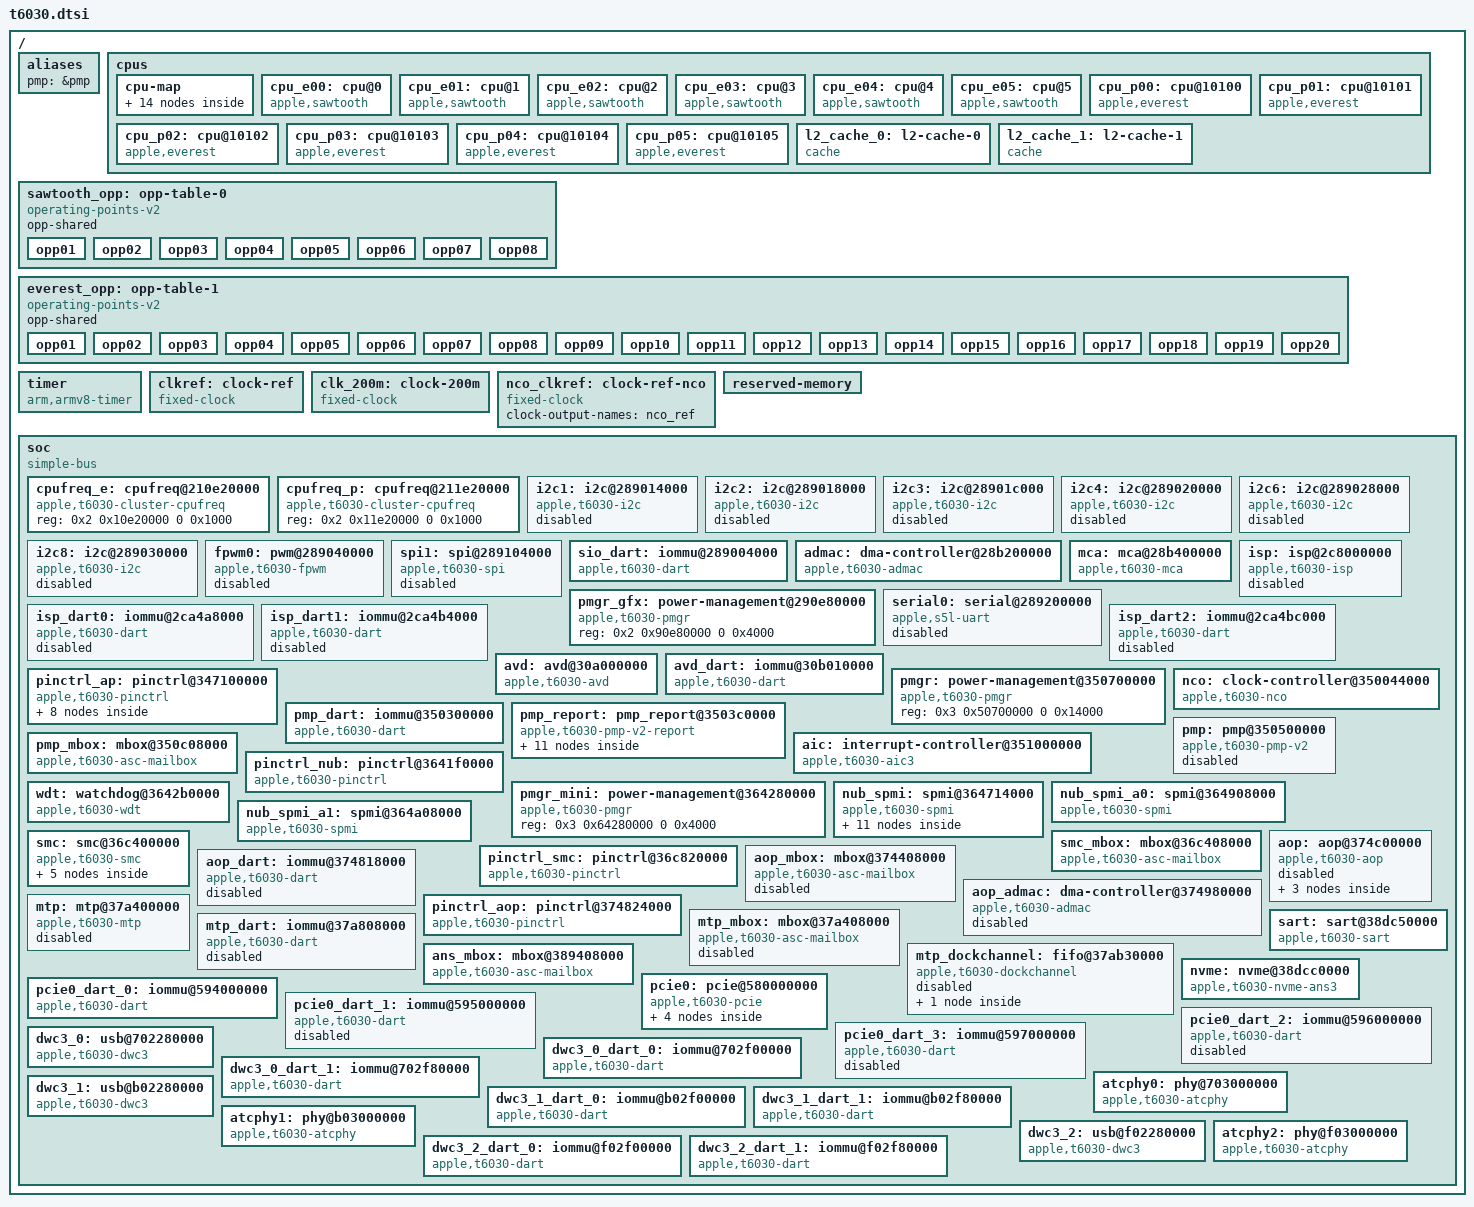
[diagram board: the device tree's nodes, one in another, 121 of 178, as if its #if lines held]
// SPDX-License-Identifier: GPL-2.0+ OR MIT
/*
 * Apple T6030 "M3 Pro" SoC
 *
 * Other names: H15J, "Lobos"
 *
 * Copyright The Asahi Linux Contributors
 */

#include <dt-bindings/gpio/gpio.h>
#include <dt-bindings/interrupt-controller/apple-aic.h>
#include <dt-bindings/interrupt-controller/irq.h>
#include <dt-bindings/pinctrl/apple.h>
#include <dt-bindings/phy/phy.h>
#include <dt-bindings/spmi/spmi.h>

/ {
	#address-cells = <2>;
	#size-cells = <2>;

	aliases {
		#ifdef APPLE_USE_PMP
		pmp = &pmp;
		#endif
	};

	cpus {
		#address-cells = <2>;
		#size-cells = <0>;

		cpu-map {
			cluster0 {
				core0 {
					cpu = <&cpu_e00>;
				};
				core1 {
					cpu = <&cpu_e01>;
				};
				core2 {
					cpu = <&cpu_e02>;
				};
				core3 {
					cpu = <&cpu_e03>;
				};
				core4 {
					cpu = <&cpu_e04>;
				};
				core5 {
					cpu = <&cpu_e05>;
				};
			};

			cluster1 {
				core0 {
					cpu = <&cpu_p00>;
				};
				core1 {
					cpu = <&cpu_p01>;
				};
				core2 {
					cpu = <&cpu_p02>;
				};
				core3 {
					cpu = <&cpu_p03>;
				};
				core4 {
					cpu = <&cpu_p04>;
				};
				core5 {
					cpu = <&cpu_p05>;
				};
			};
		};

		cpu_e00: cpu@0 {
			compatible = "apple,sawtooth";
			device_type = "cpu";
			reg = <0x0 0x0>;
			enable-method = "spin-table";
			cpu-release-addr = <0 0>; /* to be filled by loader */
			next-level-cache = <&l2_cache_0>;
			i-cache-size = <0x20000>;
			d-cache-size = <0x10000>;
			operating-points-v2 = <&sawtooth_opp>;
			capacity-dmips-mhz = <851>;
			performance-domains = <&cpufreq_e>;
		};

		cpu_e01: cpu@1 {
			compatible = "apple,sawtooth";
			device_type = "cpu";
			reg = <0x0 0x1>;
			enable-method = "spin-table";
			cpu-release-addr = <0 0>; /* to be filled by loader */
			next-level-cache = <&l2_cache_0>;
			i-cache-size = <0x20000>;
			d-cache-size = <0x10000>;
			operating-points-v2 = <&sawtooth_opp>;
			capacity-dmips-mhz = <851>;
			performance-domains = <&cpufreq_e>;
		};

		cpu_e02: cpu@2 {
			compatible = "apple,sawtooth";
			device_type = "cpu";
			reg = <0x0 0x2>;
			enable-method = "spin-table";
			cpu-release-addr = <0 0>; /* to be filled by loader */
			next-level-cache = <&l2_cache_0>;
			i-cache-size = <0x20000>;
			d-cache-size = <0x10000>;
			operating-points-v2 = <&sawtooth_opp>;
			capacity-dmips-mhz = <851>;
			performance-domains = <&cpufreq_e>;
		};

		cpu_e03: cpu@3 {
			compatible = "apple,sawtooth";
			device_type = "cpu";
			reg = <0x0 0x3>;
			enable-method = "spin-table";
			cpu-release-addr = <0 0>; /* to be filled by loader */
			next-level-cache = <&l2_cache_0>;
			i-cache-size = <0x20000>;
			d-cache-size = <0x10000>;
			operating-points-v2 = <&sawtooth_opp>;
			capacity-dmips-mhz = <851>;
			performance-domains = <&cpufreq_e>;
		};

		cpu_e04: cpu@4 {
			compatible = "apple,sawtooth";
			device_type = "cpu";
			reg = <0x0 0x4>;
			enable-method = "spin-table";
			cpu-release-addr = <0 0>; /* to be filled by loader */
			next-level-cache = <&l2_cache_0>;
			i-cache-size = <0x20000>;
			d-cache-size = <0x10000>;
			operating-points-v2 = <&sawtooth_opp>;
			capacity-dmips-mhz = <851>;
			performance-domains = <&cpufreq_e>;
		};

		cpu_e05: cpu@5 {
			compatible = "apple,sawtooth";
			device_type = "cpu";
			reg = <0x0 0x5>;
			enable-method = "spin-table";
			cpu-release-addr = <0 0>; /* to be filled by loader */
			next-level-cache = <&l2_cache_0>;
			i-cache-size = <0x20000>;
			d-cache-size = <0x10000>;
			operating-points-v2 = <&sawtooth_opp>;
			capacity-dmips-mhz = <851>;
			performance-domains = <&cpufreq_e>;
		};

		cpu_p00: cpu@10100 {
			compatible = "apple,everest";
			device_type = "cpu";
			reg = <0x0 0x10100>;
			enable-method = "spin-table";
			cpu-release-addr = <0 0>; /* To be filled by loader */
			next-level-cache = <&l2_cache_1>;
			i-cache-size = <0x30000>;
			d-cache-size = <0x20000>;
			operating-points-v2 = <&everest_opp>;
			capacity-dmips-mhz = <1024>;
			performance-domains = <&cpufreq_p>;
		};

		cpu_p01: cpu@10101 {
			compatible = "apple,everest";
			device_type = "cpu";
			reg = <0x0 0x10101>;
			enable-method = "spin-table";
			cpu-release-addr = <0 0>; /* To be filled by loader */
			next-level-cache = <&l2_cache_1>;
			i-cache-size = <0x30000>;
			d-cache-size = <0x20000>;
			operating-points-v2 = <&everest_opp>;
			capacity-dmips-mhz = <1024>;
			performance-domains = <&cpufreq_p>;
		};

		cpu_p02: cpu@10102 {
			compatible = "apple,everest";
			device_type = "cpu";
			reg = <0x0 0x10102>;
			enable-method = "spin-table";
			cpu-release-addr = <0 0>; /* To be filled by loader */
			next-level-cache = <&l2_cache_1>;
			i-cache-size = <0x30000>;
			d-cache-size = <0x20000>;
			operating-points-v2 = <&everest_opp>;
			capacity-dmips-mhz = <1024>;
			performance-domains = <&cpufreq_p>;
		};

		cpu_p03: cpu@10103 {
			compatible = "apple,everest";
			device_type = "cpu";
			reg = <0x0 0x10103>;
			enable-method = "spin-table";
			cpu-release-addr = <0 0>; /* To be filled by loader */
			next-level-cache = <&l2_cache_1>;
			i-cache-size = <0x30000>;
			d-cache-size = <0x20000>;
			operating-points-v2 = <&everest_opp>;
			capacity-dmips-mhz = <1024>;
			performance-domains = <&cpufreq_p>;
		};

		cpu_p04: cpu@10104 {
			compatible = "apple,everest";
			device_type = "cpu";
			reg = <0x0 0x10104>;
			enable-method = "spin-table";
			cpu-release-addr = <0 0>; /* To be filled by loader */
			next-level-cache = <&l2_cache_1>;
			i-cache-size = <0x30000>;
			d-cache-size = <0x20000>;
			operating-points-v2 = <&everest_opp>;
			capacity-dmips-mhz = <1024>;
			performance-domains = <&cpufreq_p>;
		};

		cpu_p05: cpu@10105 {
			compatible = "apple,everest";
			device_type = "cpu";
			reg = <0x0 0x10105>;
			enable-method = "spin-table";
			cpu-release-addr = <0 0>; /* To be filled by loader */
			next-level-cache = <&l2_cache_1>;
			i-cache-size = <0x30000>;
			d-cache-size = <0x20000>;
			operating-points-v2 = <&everest_opp>;
			capacity-dmips-mhz = <1024>;
			performance-domains = <&cpufreq_p>;
		};

		l2_cache_0: l2-cache-0 {
			compatible = "cache";
			cache-level = <2>;
			cache-unified;
			cache-size = <0x400000>;
		};

		l2_cache_1: l2-cache-1 {
			compatible = "cache";
			cache-level = <2>;
			cache-unified;
			cache-size = <0x1000000>;
		};
	};

	sawtooth_opp: opp-table-0 {
		compatible = "operating-points-v2";
		opp-shared;

		opp01 {
			opp-hz = /bits/ 64 <744000000>;
			opp-level = <1>;
			clock-latency-ns = <7700>;
		};
		opp02 {
			opp-hz = /bits/ 64 <1044000000>;
			opp-level = <2>;
			clock-latency-ns = <21200>;
		};
		opp03 {
			opp-hz = /bits/ 64 <1476000000>;
			opp-level = <3>;
			clock-latency-ns = <26400>;
		};
		opp04 {
			opp-hz = /bits/ 64 <2004000000>;
			opp-level = <4>;
			clock-latency-ns = <40500>;
		};
		opp05 {
			opp-hz = /bits/ 64 <2268000000>;
			opp-level = <5>;
			clock-latency-ns = <44400>;
		};
		opp06 {
			opp-hz = /bits/ 64 <2448000000>;
			opp-level = <6>;
			clock-latency-ns = <47200>;
		};
		opp07 {
			opp-hz = /bits/ 64 <2640000000>;
			opp-level = <7>;
			clock-latency-ns = <52000>;
		};
		opp08 {
			opp-hz = /bits/ 64 <2748000000>;
			opp-level = <8>;
			clock-latency-ns = <52000>;
		};
	};

	everest_opp: opp-table-1 {
		compatible = "operating-points-v2";
		opp-shared;

		opp01 {
			opp-hz = /bits/ 64 <696000000>;
			opp-level = <1>;
			clock-latency-ns = <8600>;
		};
		opp02 {
			opp-hz = /bits/ 64 <1092000000>;
			opp-level = <2>;
			clock-latency-ns = <18700>;
		};
		opp03 {
			opp-hz = /bits/ 64 <1356000000>;
			opp-level = <3>;
			clock-latency-ns = <20700>;
		};
		opp04 {
			opp-hz = /bits/ 64 <1596000000>;
			opp-level = <4>;
			clock-latency-ns = <24800>;
		};
		opp05 {
			opp-hz = /bits/ 64 <1884000000>;
			opp-level = <5>;
			clock-latency-ns = <30700>;
		};
		opp06 {
			opp-hz = /bits/ 64 <2172000000>;
			opp-level = <6>;
			clock-latency-ns = <34400>;
		};
		opp07 {
			opp-hz = /bits/ 64 <2424000000>;
			opp-level = <7>;
			clock-latency-ns = <39600>;
		};
		opp08 {
			opp-hz = /bits/ 64 <2616000000>;
			opp-level = <8>;
			clock-latency-ns = <40000>;
		};
		opp09 {
			opp-hz = /bits/ 64 <2808000000>;
			opp-level = <9>;
			clock-latency-ns = <41800>;
		};
		opp10 {
			opp-hz = /bits/ 64 <2988000000>;
			opp-level = <10>;
			clock-latency-ns = <45300>;
		};
		opp11 {
			opp-hz = /bits/ 64 <3144000000>;
			opp-level = <11>;
			clock-latency-ns = <46700>;
		};
		opp12 {
			opp-hz = /bits/ 64 <3288000000>;
			opp-level = <12>;
			clock-latency-ns = <49200>;
		};
		opp13 {
			opp-hz = /bits/ 64 <3420000000>;
			opp-level = <13>;
			clock-latency-ns = <53900>;
		};
		opp14 {
			opp-hz = /bits/ 64 <3576000000>;
			opp-level = <14>;
			clock-latency-ns = <53700>;
		};
		opp15 {
			opp-hz = /bits/ 64 <3624000000>;
			opp-level = <15>;
			clock-latency-ns = <54000>;
		};
		opp16 {
			opp-hz = /bits/ 64 <3708000000>;
			opp-level = <16>;
			clock-latency-ns = <54000>;
		};
		opp17 {
			opp-hz = /bits/ 64 <3780000000>;
			opp-level = <17>;
			clock-latency-ns = <54100>;
		};
		opp18 {
			opp-hz = /bits/ 64 <3864000000>;
			opp-level = <18>;
			clock-latency-ns = <54300>;
		};
		opp19 {
			opp-hz = /bits/ 64 <3960000000>;
			opp-level = <19>;
			clock-latency-ns = <58400>;
		};
		opp20 {
			opp-hz = /bits/ 64 <4056000000>;
			opp-level = <20>;
			clock-latency-ns = <58700>;
		};
	};

	timer {
		compatible = "arm,armv8-timer";
		interrupt-parent = <&aic>;
		interrupt-names = "phys", "virt", "hyp-phys", "hyp-virt";
		interrupts = <AIC_FIQ AIC_TMR_GUEST_PHYS IRQ_TYPE_LEVEL_HIGH>,
			     <AIC_FIQ AIC_TMR_GUEST_VIRT IRQ_TYPE_LEVEL_HIGH>,
			     <AIC_FIQ AIC_TMR_HV_PHYS IRQ_TYPE_LEVEL_HIGH>,
			     <AIC_FIQ AIC_TMR_HV_VIRT IRQ_TYPE_LEVEL_HIGH>;
	};

	clkref: clock-ref {
		compatible = "fixed-clock";
		#clock-cells = <0>;
		clock-frequency = <24000000>;
		clock-output-names = "clkref";
	};

	clk_200m: clock-200m {
		compatible = "fixed-clock";
		#clock-cells = <0>;
		clock-frequency = <200000000>;
		clock-output-names = "clk_200m";
	};

	/*
	 * This is a fabulated representation of the input clock
	 * to NCO since we don't know the true clock tree.
	 */
	nco_clkref: clock-ref-nco {
		compatible = "fixed-clock";
		#clock-cells = <0>;
		clock-output-names = "nco_ref";
	};

	reserved-memory {
		#address-cells = <2>;
		#size-cells = <2>;
		ranges;
	};

	soc: soc {
		compatible = "simple-bus";
		#address-cells = <2>;
		#size-cells = <2>;

		ranges;
		nonposted-mmio;
		/* Required to get >32-bit DMA via DARTs */
		dma-ranges = <0 0 0 0 0xffffffff 0xffffc000>;

		cpufreq_e: cpufreq@210e20000 {
			compatible = "apple,t6030-cluster-cpufreq", "apple,t8112-cluster-cpufreq";
			reg = <0x2 0x10e20000 0 0x1000>;
			#performance-domain-cells = <0>;
		};

		cpufreq_p: cpufreq@211e20000 {
			compatible = "apple,t6030-cluster-cpufreq", "apple,t8112-cluster-cpufreq";
			reg = <0x2 0x11e20000 0 0x1000>;
			#performance-domain-cells = <0>;
		};

		i2c1: i2c@289014000 {
			compatible = "apple,t6030-i2c", "apple,t8103-i2c";
			reg = <0x2 0x89014000 0x0 0x4000>;
			clocks = <&clkref>;
			interrupt-parent = <&aic>;
			interrupts = <AIC_IRQ 890 IRQ_TYPE_LEVEL_HIGH>;
			pinctrl-0 = <&i2c1_pins>;
			pinctrl-names = "default";
			#address-cells = <0x1>;
			#size-cells = <0x0>;
			power-domains = <&ps_i2c1>;
			status = "disabled";
		};

		i2c2: i2c@289018000 {
			compatible = "apple,t6030-i2c", "apple,t8103-i2c";
			reg = <0x2 0x89018000 0x0 0x4000>;
			clocks = <&clkref>;
			interrupt-parent = <&aic>;
			interrupts = <AIC_IRQ 891 IRQ_TYPE_LEVEL_HIGH>;
			pinctrl-0 = <&i2c2_pins>;
			pinctrl-names = "default";
			#address-cells = <0x1>;
			#size-cells = <0x0>;
			power-domains = <&ps_i2c2>;
			status = "disabled";
		};

		i2c3: i2c@28901c000 {
			compatible = "apple,t6030-i2c", "apple,t8103-i2c";
			reg = <0x2 0x8901c000 0x0 0x4000>;
			clocks = <&clkref>;
			interrupt-parent = <&aic>;
			interrupts = <AIC_IRQ 892 IRQ_TYPE_LEVEL_HIGH>;
			pinctrl-0 = <&i2c3_pins>;
			pinctrl-names = "default";
			#address-cells = <0x1>;
			#size-cells = <0x0>;
			power-domains = <&ps_i2c3>;
			status = "disabled";
		};

		i2c4: i2c@289020000 {
			compatible = "apple,t6030-i2c", "apple,t8103-i2c";
			reg = <0x2 0x89020000 0x0 0x4000>;
			clocks = <&clkref>;
			interrupt-parent = <&aic>;
			interrupts = <AIC_IRQ 893 IRQ_TYPE_LEVEL_HIGH>;
			pinctrl-0 = <&i2c4_pins>;
			pinctrl-names = "default";
			#address-cells = <0x1>;
			#size-cells = <0x0>;
			power-domains = <&ps_i2c4>;
			status = "disabled";
		};

		i2c6: i2c@289028000 {
			compatible = "apple,t6030-i2c", "apple,t8103-i2c";
			reg = <0x2 0x89028000 0x0 0x4000>;
			clocks = <&clkref>;
			interrupt-parent = <&aic>;
			interrupts = <AIC_IRQ 895 IRQ_TYPE_LEVEL_HIGH>;
			pinctrl-0 = <&i2c6_pins>;
			pinctrl-names = "default";
			#address-cells = <0x1>;
			#size-cells = <0x0>;
			power-domains = <&ps_i2c6>;
			status = "disabled";
		};

		i2c8: i2c@289030000 {
			compatible = "apple,t6030-i2c", "apple,t8103-i2c";
			reg = <0x2 0x89030000 0x0 0x4000>;
			clocks = <&clkref>;
			interrupt-parent = <&aic>;
			interrupts = <AIC_IRQ 897 IRQ_TYPE_LEVEL_HIGH>;
			pinctrl-0 = <&i2c8_pins>;
			pinctrl-names = "default";
			#address-cells = <0x1>;
			#size-cells = <0x0>;
			power-domains = <&ps_i2c8>;
			status = "disabled";
		};

		fpwm0: pwm@289040000 {
			compatible = "apple,t6030-fpwm", "apple,s5l-fpwm";
			reg = <0x2 0x89040000 0x0 0x4000>;
			power-domains = <&ps_fpwm0>;
			clocks = <&clkref>;
			#pwm-cells = <2>;
			status = "disabled";
		};

		spi1: spi@289104000 {
			compatible = "apple,t6030-spi", "apple,t8103-spi";
			reg = <0x2 0x89104000 0x0 0x4000>;
			interrupt-parent = <&aic>;
			interrupts = <AIC_IRQ 875 IRQ_TYPE_LEVEL_HIGH>;
			#address-cells = <1>;
			#size-cells = <0>;
			clocks = <&clk_200m>;
			pinctrl-0 = <&spi1_pins>;
			pinctrl-names = "default";
			power-domains = <&ps_spi1>;
			status = "disabled";
		};

		sio_dart: iommu@289004000 {
			compatible = "apple,t6030-dart", "apple,t8110-dart";
			reg = <0x2 0x89004000 0x0 0x4000>;
			interrupt-parent = <&aic>;
			interrupts = <AIC_IRQ 901 IRQ_TYPE_LEVEL_HIGH>;
			#iommu-cells = <1>;
			power-domains = <&ps_sio>;
			//apple,dma-range = <0x100 0x0001c000 0x2ff 0xfffe4000>;
		};

		admac: dma-controller@28b200000 {
			compatible = "apple,t6030-admac", "apple,t8122-admac";
			reg = <0x2 0x8b200000 0x0 0x34000>;
			#dma-cells = <1>;
			dma-channels = <24>;
			interrupts-extended = <0>,
					      <&aic AIC_IRQ 888 IRQ_TYPE_LEVEL_HIGH>,
					      <0>,
					      <0>;
			iommus = <&sio_dart 2>;
			power-domains = <&ps_sio_adma>;
			resets = <&ps_audio_p>;
		};

		mca: mca@28b400000 {
			compatible = "apple,t6030-mca", "apple,t8103-mca";
			reg = <0x2 0x8b400000 0x0 0x10000>,
			      <0x2 0x8b300000 0x0 0x20000>;
			clocks = <&nco 0>, <&nco 1>, <&nco 2>, <&nco 3>;
			dmas = <&admac 0>, <&admac 1>, <&admac 2>, <&admac 3>,
			       <&admac 4>, <&admac 5>, <&admac 6>, <&admac 7>,
			       <&admac 8>, <&admac 9>, <&admac 10>, <&admac 11>,
			       <&admac 12>, <&admac 13>, <&admac 14>, <&admac 15>;
			dma-names = "tx0a", "rx0a", "tx0b", "rx0b",
				    "tx1a", "rx1a", "tx1b", "rx1b",
				    "tx2a", "rx2a", "tx2b", "rx2b",
				    "tx3a", "rx3a", "tx3b", "rx3b";
			interrupt-parent = <&aic>;
			interrupts = <AIC_IRQ 881 IRQ_TYPE_LEVEL_HIGH>,
				     <AIC_IRQ 882 IRQ_TYPE_LEVEL_HIGH>,
				     <AIC_IRQ 883 IRQ_TYPE_LEVEL_HIGH>,
				     <AIC_IRQ 884 IRQ_TYPE_LEVEL_HIGH>;
			power-domains = <&ps_audio_p>, <&ps_mca0>, <&ps_mca1>,
					<&ps_mca2>, <&ps_mca3>;
			resets = <&ps_audio_p>;
			#sound-dai-cells = <1>;
		};

		pmgr_gfx: power-management@290e80000 {
			compatible = "apple,t6030-pmgr", "apple,t8103-pmgr", "syscon", "simple-mfd";
			#address-cells = <1>;
			#size-cells = <1>;

			reg = <0x2 0x90e80000 0 0x4000>;
			/* child nodes are added in t6030-pmgr.dtsi */
		};

		serial0: serial@289200000 {
			compatible = "apple,s5l-uart";
			reg = <0x2 0x89200000 0x0 0x1000>;
			reg-io-width = <4>;
			interrupt-parent = <&aic>;
			interrupts = <AIC_IRQ 866 IRQ_TYPE_LEVEL_HIGH>;
			/*
			 * TODO: figure out the clocking properly, there may
			 * be a third selectable clock.
			 */
			clocks = <&clkref>, <&clkref>;
			clock-names = "uart", "clk_uart_baud0";
			power-domains = <&ps_uart0>;
			status = "disabled";
		};

		isp: isp@2c8000000 {
			compatible = "apple,t6030-isp";
			iommus = <&isp_dart0 0>, <&isp_dart1 0>, <&isp_dart2 0>;
			reg-names = "coproc", "mbox", "gpio", "mbox2";
			reg = <0x2 0xc8000000 0x0 0x2000000>,
				<0x2 0xca4c4000 0x0 0x100>,
				<0x2 0xca4c41d0 0x0 0x100>,
				<0x2 0xca4c4458 0x0 0x100>;
			interrupt-parent = <&aic>;
			interrupts = <AIC_IRQ 359 IRQ_TYPE_LEVEL_HIGH>;
			power-domains = <&ps_isp_sys>, <&ps_ispsens0>,
				<&ps_isp_cpu>, <&ps_isp_fe>, <&ps_dprx>,
				<&ps_isp_secure>, <&ps_isp_be>, <&ps_isp_clr>;
			apple,dart-vm-size = <0x0 0xa0000000>;

			status = "disabled";
		};

		isp_dart0: iommu@2ca4a8000 {
			compatible = "apple,t6030-dart", "apple,t8110-dart";
			reg = <0x2 0xca4a8000 0x0 0x4000>;
			#iommu-cells = <1>;
			interrupt-parent = <&aic>;
			interrupts = <AIC_IRQ 364 IRQ_TYPE_LEVEL_HIGH>;
			power-domains = <&ps_isp_sys>;
			status = "disabled";
		};

		isp_dart1: iommu@2ca4b4000 {
			compatible = "apple,t6030-dart", "apple,t8110-dart";
			reg = <0x2 0xca4b4000 0x0 0x4000>;
			#iommu-cells = <1>;
			interrupt-parent = <&aic>;
			interrupts = <AIC_IRQ 364 IRQ_TYPE_LEVEL_HIGH>;
			power-domains = <&ps_isp_sys>;
			status = "disabled";
		};

		isp_dart2: iommu@2ca4bc000 {
			compatible = "apple,t6030-dart", "apple,t8110-dart";
			reg = <0x2 0xca4bc000 0x0 0x4000>;
			#iommu-cells = <1>;
			interrupt-parent = <&aic>;
			interrupts = <AIC_IRQ 364 IRQ_TYPE_LEVEL_HIGH>;
			power-domains = <&ps_isp_sys>;
			status = "disabled";
		};

		avd: avd@30a000000 {
			compatible = "apple,t6030-avd", "apple,t8122-avd";
			interrupt-parent = <&aic>;
			interrupts = <AIC_IRQ 788 IRQ_TYPE_LEVEL_HIGH>,
				<AIC_IRQ 789 IRQ_TYPE_LEVEL_HIGH>;
			#if defined(APPLE_USE_PMP)
			power-domains = <&pmp_report_avd_sys>;
			#else
			power-domains = <&ps_avd_sys>;
			#endif
			resets = <&ps_avd_sys>;
			reg = <0x3 0x0b080000 0x0 0x12000>,
				<0x3 0x0b092000 0x0 0x12000>,
				<0x3 0x0b0a4000 0x0 0x4000>,
				<0x3 0x0b100000 0x0 0x10000>;
			reg-names = "code", "sram", "mbox", "ctrl";
			iommus = <&avd_dart 0>;
		};

		avd_dart: iommu@30b010000 {
			compatible = "apple,t6030-dart", "apple,t8110-dart";
			reg = <0x3 0x0b010000 0x0 0x4000>;
			#iommu-cells = <1>;
			interrupt-parent = <&aic>;
			interrupts = <AIC_IRQ 795 IRQ_TYPE_LEVEL_HIGH>;
			power-domains = <&ps_avd_sys>;
		};

		pinctrl_ap: pinctrl@347100000 {
			compatible = "apple,t6030-pinctrl", "apple,t8103-pinctrl";
			reg = <0x3 0x47100000 0x0 0x4000>;

			interrupt-parent = <&aic>;
			interrupts = <AIC_IRQ 273 IRQ_TYPE_LEVEL_HIGH>,
				     <AIC_IRQ 274 IRQ_TYPE_LEVEL_HIGH>,
				     <AIC_IRQ 275 IRQ_TYPE_LEVEL_HIGH>,
				     <AIC_IRQ 276 IRQ_TYPE_LEVEL_HIGH>,
				     <AIC_IRQ 277 IRQ_TYPE_LEVEL_HIGH>,
				     <AIC_IRQ 278 IRQ_TYPE_LEVEL_HIGH>,
				     <AIC_IRQ 279 IRQ_TYPE_LEVEL_HIGH>;

			power-domains = <&ps_gpio>;

			gpio-controller;
			#gpio-cells = <2>;
			gpio-ranges = <&pinctrl_ap 0 0 224>;
			apple,npins = <224>;

			interrupt-controller;
			#interrupt-cells = <2>;

			i2c1_pins: i2c1-pins {
				pinmux = <APPLE_PINMUX(37, 1)>,
					 <APPLE_PINMUX(36, 1)>;
			};

			i2c2_pins: i2c2-pins {
				pinmux = <APPLE_PINMUX(43, 1)>,
					 <APPLE_PINMUX(42, 1)>;
			};

			i2c3_pins: i2c3-pins {
				pinmux = <APPLE_PINMUX(41, 1)>,
					 <APPLE_PINMUX(40, 1)>;
			};

			i2c4_pins: i2c4-pins {
				pinmux = <APPLE_PINMUX(39, 1)>,
					 <APPLE_PINMUX(38, 1)>;
			};

			i2c6_pins: i2c6-pins {
				pinmux = <APPLE_PINMUX(47, 1)>,
					 <APPLE_PINMUX(46, 1)>;
			};

			i2c8_pins: i2c8-pins {
				pinmux = <APPLE_PINMUX(51, 1)>,
					 <APPLE_PINMUX(50, 1)>;
			};

			spi1_pins: spi1-pins {
				pinmux = <APPLE_PINMUX(24, 1)>, /* SDI */
					<APPLE_PINMUX(25, 1)>,  /* SDO */
					<APPLE_PINMUX(26, 1)>,  /* SCK */
					<APPLE_PINMUX(27, 1)>;  /* CS */
			};

			pcie_pins: pcie-pins {
				// clkreq pins
				pinmux = <APPLE_PINMUX(163, 1)>,
					 <APPLE_PINMUX(164, 1)>,
					 <APPLE_PINMUX(165, 1)>,
					 <APPLE_PINMUX(166, 1)>;
			};
		};

		pmgr: power-management@350700000 {
			compatible = "apple,t6030-pmgr", "apple,t8103-pmgr", "syscon", "simple-mfd";
			#address-cells = <1>;
			#size-cells = <1>;

			reg = <0x3 0x50700000 0 0x14000>;
			/* child nodes are added in t6030-pmgr.dtsi */
		};

		nco: clock-controller@350044000 {
			compatible = "apple,t6030-nco", "apple,t8103-nco";
			reg = <0x3 0x50044000 0x0 0x14000>;
			clocks = <&nco_clkref>;
			#clock-cells = <1>;
		};

		pmp_dart: iommu@350300000 {
			compatible = "apple,t6030-dart", "apple,t8110-dart";
			reg = <0x3 0x50300000 0x0 0x4000>;
			#iommu-cells = <1>;
			interrupt-parent = <&aic>;
			interrupts = <AIC_IRQ 734 IRQ_TYPE_LEVEL_HIGH>;
			power-domains = <&ps_pmp>;
		};

		pmp_report: pmp_report@3503c0000 {
			compatible = "apple,t6030-pmp-v2-report";
			reg = <0x3 0x503c0000 0x0 0x20000>;
			power-domains = <&ps_pms_sram>;
			#address-cells = <1>;
			#size-cells = <0>;

			pmp_report_ane_sys: report@5 {
				compatible = "apple,t6030-pmp-v2-report-entry",
					     "apple,t6000-pmp-v2-report-entry";
				reg = <0x5>;
				label = "pmp-ane-sys";
				#power-domain-cells = <0>;
				power-domains = <&ps_ane_sys>;
				status = "disabled";
			};

			pmp_report_isp_sys: report@6 {
				compatible = "apple,t6030-pmp-v2-report-entry",
					     "apple,t6000-pmp-v2-report-entry";
				reg = <0x6>;
				label = "pmp-isp-sys";
				#power-domain-cells = <0>;
				power-domains = <&ps_isp_sys>;
				status = "disabled";
			};

			pmp_report_disp: report@7 {
				compatible = "apple,t6030-pmp-v2-report-entry",
					     "apple,t6000-pmp-v2-report-entry";
				reg = <0x7>;
				label = "pmp-disp";
				#power-domain-cells = <0>;
				power-domains = <&ps_disp_cpu>;
				apple,always-on;
			};

			pmp_report_dispext0: report@8 {
				compatible = "apple,t6030-pmp-v2-report-entry",
					     "apple,t6000-pmp-v2-report-entry";
				reg = <0x8>;
				label = "pmp-dispext0";
				#power-domain-cells = <0>;
				power-domains = <&ps_dispext0_cpu>;
			};

			pmp_report_dispext1: report@9 {
				compatible = "apple,t6030-pmp-v2-report-entry",
					     "apple,t6000-pmp-v2-report-entry";
				reg = <0x9>;
				label = "pmp-dispext1";
				#power-domain-cells = <0>;
				power-domains = <&ps_dispext1_cpu>;
			};

			pmp_report_venc_sys: report@a {
				compatible = "apple,t6030-pmp-v2-report-entry",
					     "apple,t6000-pmp-v2-report-entry";
				reg = <0xa>;
				label = "pmp-venc-sys";
				#power-domain-cells = <0>;
				power-domains = <&ps_venc_sys>;
				status = "disabled";
			};

			pmp_report_avd_sys: report@b {
				compatible = "apple,t6030-pmp-v2-report-entry",
					     "apple,t6000-pmp-v2-report-entry";
				reg = <0xb>;
				label = "pmp-avd-sys";
				#power-domain-cells = <0>;
				power-domains = <&ps_avd_sys>;
			};

			pmp_report_msr: report@c {
				compatible = "apple,t6030-pmp-v2-report-entry",
					     "apple,t6000-pmp-v2-report-entry";
				reg = <0xc>;
				label = "pmp-msr";
				#power-domain-cells = <0>;
				power-domains = <&ps_msr>;
				status = "disabled";
			};

			pmp_report_jpg: report@d {
				compatible = "apple,t6030-pmp-v2-report-entry",
					     "apple,t6000-pmp-v2-report-entry";
				reg = <0xd>;
				label = "pmp-jpg";
				#power-domain-cells = <0>;
				power-domains = <&ps_jpg>;
				status = "disabled";
			};

			pmp_report_scodec: report@e {
				compatible = "apple,t6030-pmp-v2-report-entry",
					     "apple,t6000-pmp-v2-report-entry";
				reg = <0xe>;
				label = "pmp-scodec";
				#power-domain-cells = <0>;
				power-domains = <&ps_scodec>;
				status = "disabled";
			};

			pmp_report_ans: report@10 {
				compatible = "apple,t6030-pmp-v2-report-entry",
					     "apple,t6000-pmp-v2-report-entry";
				reg = <0x10>;
				label = "pmp-ans";
				#power-domain-cells = <0>;
				power-domains = <&ps_ans>;
			};
		};

		pmp: pmp@350500000 {
			compatible = "apple,t6030-pmp-v2", "apple,t6000-pmp-v2";
			reg = <0x3 0x50500000 0x0 0x80000>,
			      <0x3 0x50c00000 0x0 0x4000>;
			reg-names = "pmp", "asc";
			mboxes = <&pmp_mbox>;
			mbox-names = "mbox";
			iommus = <&pmp_dart 0>;
			power-domains = <&ps_pmp>;
			status = "disabled";
		};

		pmp_mbox: mbox@350c08000 {
			compatible = "apple,t6030-asc-mailbox", "apple,asc-mailbox-v4";
			reg = <0x3 0x50c08000 0x0 0x4000>;
			interrupt-parent = <&aic>;
			interrupts = <AIC_IRQ 730 IRQ_TYPE_LEVEL_HIGH>,
			             <AIC_IRQ 731 IRQ_TYPE_LEVEL_HIGH>,
			             <AIC_IRQ 732 IRQ_TYPE_LEVEL_HIGH>,
			             <AIC_IRQ 733 IRQ_TYPE_LEVEL_HIGH>;
			interrupt-names = "send-empty", "send-not-empty",
			                  "recv-empty", "recv-not-empty";
			#mbox-cells = <0>;
			power-domains = <&ps_pmp>, <&ps_pms_sram>;
		};

		aic: interrupt-controller@351000000 {
			compatible = "apple,t6030-aic3", "apple,t8122-aic3";
			#interrupt-cells = <3>;
			interrupt-controller;

			reg = <0x3 0x51000000 0x0 0x184000>,
			      <0x3 0x51040000 0x0 0x4000>;
			reg-names = "core", "event";
			power-domains = <&ps_aic>;
		};

		pinctrl_nub: pinctrl@3641f0000 {
			compatible = "apple,t6030-pinctrl", "apple,t8103-pinctrl";
			reg = <0x3 0x641f0000 0x0 0x4000>;

			interrupt-parent = <&aic>;
			interrupts = <AIC_IRQ 472 IRQ_TYPE_LEVEL_HIGH>,
				     <AIC_IRQ 473 IRQ_TYPE_LEVEL_HIGH>,
				     <AIC_IRQ 474 IRQ_TYPE_LEVEL_HIGH>,
				     <AIC_IRQ 475 IRQ_TYPE_LEVEL_HIGH>,
				     <AIC_IRQ 476 IRQ_TYPE_LEVEL_HIGH>,
				     <AIC_IRQ 477 IRQ_TYPE_LEVEL_HIGH>,
				     <AIC_IRQ 478 IRQ_TYPE_LEVEL_HIGH>;

			gpio-controller;
			#gpio-cells = <2>;
			gpio-ranges = <&pinctrl_nub 0 0 37>;
			apple,npins = <37>;

			interrupt-controller;
			#interrupt-cells = <2>;
		};

		pmgr_mini: power-management@364280000 {
			compatible = "apple,t6030-pmgr", "apple,t8103-pmgr", "syscon", "simple-mfd";
			#address-cells = <1>;
			#size-cells = <1>;

			reg = <0x3 0x64280000 0 0x4000>;
			/* child nodes are added in t6030-pmgr.dtsi */
		};

		wdt: watchdog@3642b0000 {
			compatible = "apple,t6030-wdt", "apple,t8103-wdt";
			reg = <0x3 0x642b0000 0x0 0x4000>;
			clocks = <&clkref>;
			interrupt-parent = <&aic>;
			interrupts = <AIC_IRQ 480 IRQ_TYPE_LEVEL_HIGH>;
		};

		nub_spmi: spmi@364714000 {
			compatible = "apple,t6030-spmi", "apple,t8103-spmi";
			reg = <0x3 0x64714000 0x0 0x100>;
			#address-cells = <2>;
			#size-cells = <0>;
			interrupt-parent = <&aic>;
			interrupts = <AIC_IRQ 485 IRQ_TYPE_LEVEL_HIGH>;

			pmic1: pmic@b {
				compatible = "apple,chapel-pmic", "apple,spmi-nvmem";
				reg = <0xb SPMI_USID>;

				nvmem-layout {
					compatible = "fixed-layout";
					#address-cells = <1>;
					#size-cells = <1>;

					pm_setting: pm-setting@2001 {
						reg = <0x2001 0x1>;
					};

					rtc_offset: rtc-offset@2100 {
						reg = <0x2100 0x6>;
					};

					fault_shadow: fault-shadow@867b {
						reg = <0x867b 0x10>;
					};

					socd: socd@8b00 {
						reg = <0x8b00 0x400>;
					};

					boot_stage: boot-stage@f801 {
						reg = <0xf801 0x1>;
					};

					boot_error_count: boot-error-count@f802,0 {
						reg = <0xf802 0x1>;
						bits = <0 4>;
					};

					panic_count: panic-count@f802,4 {
						reg = <0xf802 0x1>;
						bits = <4 4>;
					};

					boot_error_stage: boot-error-stage@f803 {
						reg = <0xf803 0x1>;
					};

					shutdown_flag: shutdown-flag@f80f,3 {
						reg = <0xf80f 0x1>;
						bits = <3 1>;
					};
				};
			};
		};

		nub_spmi_a0: spmi@364908000 {
			compatible = "apple,t6030-spmi", "apple,t8103-spmi";
			reg = <0x3 0x64908000 0x0 0x100>;
			#address-cells = <2>;
			#size-cells = <0>;
			#interrupt-cells = <2>;
			interrupt-controller;
			interrupt-parent = <&aic>;
			interrupts = <AIC_IRQ 509 IRQ_TYPE_LEVEL_HIGH>;
			power-domains = <&ps_nub_spmi_a0>;
		};

		nub_spmi_a1: spmi@364a08000 {
			compatible = "apple,t6030-spmi", "apple,t8103-spmi";
			reg = <0x3 0x64a08000 0x0 0x100>;
			#address-cells = <2>;
			#size-cells = <0>;
			#interrupt-cells = <2>;
			interrupt-controller;
			interrupt-parent = <&aic>;
			interrupts = <AIC_IRQ 511 IRQ_TYPE_LEVEL_HIGH>;
			power-domains = <&ps_nub_spmi_a1>;
		};

		smc_mbox: mbox@36c408000 {
			compatible = "apple,t6030-asc-mailbox", "apple,asc-mailbox-v4";
			reg = <0x3 0x6c408000 0x0 0x4000>;
			interrupt-parent = <&aic>;
			interrupts = <AIC_IRQ 554 IRQ_TYPE_LEVEL_HIGH>,
				<AIC_IRQ 555 IRQ_TYPE_LEVEL_HIGH>,
				<AIC_IRQ 556 IRQ_TYPE_LEVEL_HIGH>,
				<AIC_IRQ 557 IRQ_TYPE_LEVEL_HIGH>;
			interrupt-names = "send-empty", "send-not-empty",
				"recv-empty", "recv-not-empty";
			#mbox-cells = <0>;
		};

		smc: smc@36c400000 {
			compatible = "apple,t6030-smc", "apple,t8103-smc";
			reg = <0x3 0x6c400000 0x0 0x4000>,
			      <0x3 0x6de00000 0x0 0x100000>;
			reg-names = "smc", "sram";
			mboxes = <&smc_mbox>;

			smc_gpio: gpio@67500000 {
				compatible = "apple,smc-gpio";
				gpio-controller;
				#gpio-cells = <2>;
			};

			smc_gpio_low: gpio@67700000 {
				compatible = "apple,smc-low-gpio";
				gpio-controller;
				#gpio-cells = <2>;
			};

			smc_hwmon: hwmon {
				compatible = "apple,smc-hwmon";
			};

			smc_reboot: reboot {
				compatible = "apple,smc-reboot";
				nvmem-cells = <&shutdown_flag>, <&boot_stage>,
					<&boot_error_count>, <&panic_count>;
				nvmem-cell-names = "shutdown_flag", "boot_stage",
					"boot_error_count", "panic_count";
			};

			rtc {
				compatible = "apple,smc-rtc";
				nvmem-cells = <&rtc_offset>;
				nvmem-cell-names = "rtc_offset";
			};
		};

		pinctrl_smc: pinctrl@36c820000 {
			compatible = "apple,t6030-pinctrl", "apple,t8103-pinctrl";
			reg = <0x3 0x6c820000 0x0 0x4000>;

			gpio-controller;
			#gpio-cells = <2>;
			gpio-ranges = <&pinctrl_smc 0 0 18>;
			apple,npins = <18>;

			interrupt-controller;
			#interrupt-cells = <2>;
			interrupt-parent = <&aic>;
			interrupts = <AIC_IRQ 545 IRQ_TYPE_LEVEL_HIGH>,
				     <AIC_IRQ 546 IRQ_TYPE_LEVEL_HIGH>,
				     <AIC_IRQ 547 IRQ_TYPE_LEVEL_HIGH>,
				     <AIC_IRQ 548 IRQ_TYPE_LEVEL_HIGH>,
				     <AIC_IRQ 549 IRQ_TYPE_LEVEL_HIGH>,
				     <AIC_IRQ 550 IRQ_TYPE_LEVEL_HIGH>,
				     <AIC_IRQ 551 IRQ_TYPE_LEVEL_HIGH>;
		};

		aop_mbox: mbox@374408000 {
			compatible = "apple,t6030-asc-mailbox", "apple,asc-mailbox-v4";
			reg = <0x3 0x74408000 0x0 0x4000>;
			interrupt-parent = <&aic>;
			interrupts = <AIC_IRQ 419 IRQ_TYPE_LEVEL_HIGH>,
				<AIC_IRQ 420 IRQ_TYPE_LEVEL_HIGH>,
				<AIC_IRQ 421 IRQ_TYPE_LEVEL_HIGH>,
				<AIC_IRQ 422 IRQ_TYPE_LEVEL_HIGH>;
			interrupt-names = "send-empty", "send-not-empty",
				"recv-empty", "recv-not-empty";
			#mbox-cells = <0>;
			status = "disabled";
		};

		aop_dart: iommu@374818000 {
			compatible = "apple,t6030-dart", "apple,t8110-dart";
			reg = <0x3 0x74818000 0x0 0x4000>;
			#iommu-cells = <1>;
			interrupt-parent = <&aic>;
			interrupts = <AIC_IRQ 439 IRQ_TYPE_LEVEL_HIGH>;
			status = "disabled";
			// apple,dma-range = <0x100 0x0 0x300 0x0>;
		};

		aop_admac: dma-controller@374980000 {
			compatible = "apple,t6030-admac", "apple,t8122-admac";
			reg = <0x3 0x74980000 0x0 0x34000>;
			#dma-cells = <1>;
			dma-channels = <16>;
			interrupts-extended = <0>,
					      <0>,
					      <&aic AIC_IRQ 460 IRQ_TYPE_LEVEL_HIGH>,
					      <0>;
			iommus = <&aop_dart 10>;
			status = "disabled";
		};

		aop: aop@374c00000 {
			compatible = "apple,t6030-aop", "apple,t6020-aop";
			reg = <0x3 0x74c00000 0x0 0x1e0000>,
			      <0x3 0x74400000 0x0 0x6c000>;
			mboxes = <&aop_mbox>;
			mbox-names = "mbox";
			iommus = <&aop_dart 0>;

			status = "disabled";

			aop_audio: audio {
				compatible = "apple,t6030-aop-audio";
				dmas = <&aop_admac 1>;
				dma-names = "dma";
			};

			aop_als: als {
				compatible = "apple,t6030-aop-als", "apple,t6020-aop-als", "apple,aop-als";
				// intentionally empty
			};

			las {
				compatible = "apple,t6030-aop-las", "apple,t6020-aop-las", "apple,aop-las";
			};
		};

		pinctrl_aop: pinctrl@374824000 {
			compatible = "apple,t6030-pinctrl", "apple,t8103-pinctrl";
			reg = <0x3 0x74824000 0x0 0x4000>;

			interrupt-parent = <&aic>;
			interrupts = <AIC_IRQ 394 IRQ_TYPE_LEVEL_HIGH>,
				     <AIC_IRQ 395 IRQ_TYPE_LEVEL_HIGH>,
				     <AIC_IRQ 396 IRQ_TYPE_LEVEL_HIGH>,
				     <AIC_IRQ 397 IRQ_TYPE_LEVEL_HIGH>,
				     <AIC_IRQ 398 IRQ_TYPE_LEVEL_HIGH>,
				     <AIC_IRQ 399 IRQ_TYPE_LEVEL_HIGH>,
				     <AIC_IRQ 400 IRQ_TYPE_LEVEL_HIGH>;

			clocks = <&clkref>;

			gpio-controller;
			#gpio-cells = <2>;
			gpio-ranges = <&pinctrl_aop 0 0 54>;
			apple,npins = <54>;

			interrupt-controller;
			#interrupt-cells = <2>;
		};

		mtp: mtp@37a400000 {
			compatible = "apple,t6030-mtp", "apple,t6030-rtk-helper-asc4", "apple,mtp", "apple,rtk-helper-asc4";
			reg = <0x3 0x7a400000 0x0 0x4000>,
				<0x3 0x7ac00000 0x0 0x100000>;
			reg-names = "asc", "sram";

			mboxes = <&mtp_mbox>;
			iommus = <&mtp_dart 1>;
			#helper-cells = <0>;

			status = "disabled";
		};

		mtp_mbox: mbox@37a408000 {
			compatible = "apple,t6030-asc-mailbox", "apple,asc-mailbox-v4";
			reg = <0x3 0x7a408000 0x0 0x4000>;

			interrupt-parent = <&aic>;
			interrupts = <AIC_IRQ 953 IRQ_TYPE_LEVEL_HIGH>,
				<AIC_IRQ 954 IRQ_TYPE_LEVEL_HIGH>,
				<AIC_IRQ 955 IRQ_TYPE_LEVEL_HIGH>,
				<AIC_IRQ 956 IRQ_TYPE_LEVEL_HIGH>;
			interrupt-names = "send-empty", "send-not-empty",
				"recv-empty", "recv-not-empty";
			#mbox-cells = <0>;
			status = "disabled";
		};

		mtp_dart: iommu@37a808000 {
			compatible = "apple,t6030-dart", "apple,t8110-dart";
			reg = <0x3 0x7a808000 0x0 0x4000>;

			interrupt-parent = <&aic>;
			interrupts = <AIC_IRQ 937 IRQ_TYPE_LEVEL_HIGH>;

			#iommu-cells = <1>;

			status = "disabled";
		};

		mtp_dockchannel: fifo@37ab30000 {
			compatible = "apple,t6030-dockchannel", "apple,dockchannel";
			reg = <0x3 0x7ab14000 0x0 0x4000>;
			reg-names = "irq";
			interrupt-parent = <&aic>;
			interrupts = <AIC_IRQ 939 IRQ_TYPE_LEVEL_HIGH>;

			ranges = <0 0x3 0x7ab28000 0x20000>;
			nonposted-mmio;
			#address-cells = <1>;
			#size-cells = <1>;

			interrupt-controller;
			#interrupt-cells = <2>;

			status = "disabled";

			mtp_hid: input@0 {
				compatible = "apple,dockchannel-hid";
				reg = <0x0000 0x4000>,
				      <0x4000 0x4000>,
				      <0x8000 0x4000>,
				      <0xc000 0x4000>;
				reg-names = "rmt-config", "rmt-data", "config", "data";

				iommus = <&mtp_dart 1>;

				interrupt-parent = <&mtp_dockchannel>;
				interrupts = <2 IRQ_TYPE_LEVEL_HIGH>,
					<3 IRQ_TYPE_LEVEL_HIGH>;
				interrupt-names = "tx", "rx";

				apple,fifo-size = <0x800>;
				apple,helper-cpu = <&mtp>;
			};
		};

		ans_mbox: mbox@389408000 {
			compatible = "apple,t6030-asc-mailbox", "apple,asc-mailbox-v4";
			reg = <0x3 0x89408000 0x0 0x4000>;

			interrupt-parent = <&aic>;
			interrupts = <AIC_IRQ 839 IRQ_TYPE_LEVEL_HIGH>,
				<AIC_IRQ 840 IRQ_TYPE_LEVEL_HIGH>,
				<AIC_IRQ 841 IRQ_TYPE_LEVEL_HIGH>,
				<AIC_IRQ 842 IRQ_TYPE_LEVEL_HIGH>;
			interrupt-names = "send-empty", "send-not-empty",
					  "recv-empty", "recv-not-empty";

			#mbox-cells = <0>;
			#if defined(APPLE_USE_PMP)
			power-domains = <&pmp_report_ans>;
			#else
			power-domains = <&ps_ans>;
			#endif
		};

		sart: sart@38dc50000 {
			compatible = "apple,t6030-sart", "apple,t6000-sart";
			reg = <0x3 0x8dc50000 0x0 0xc000>;
			#if defined(APPLE_USE_PMP)
			power-domains = <&pmp_report_ans>;
			#else
			power-domains = <&ps_ans>;
			#endif
		};

		nvme: nvme@38dcc0000 {
			compatible = "apple,t6030-nvme-ans3", "apple,t8103-nvme-ans2";
			reg = <0x3 0x8dcc0000 0x0 0x60000>,
			      <0x3 0x89400000 0x0 0x4000>;
			reg-names = "nvme", "ans";

			interrupt-parent = <&aic>;
			interrupts = <AIC_IRQ 851 IRQ_TYPE_LEVEL_HIGH>;

			mboxes = <&ans_mbox>;
			apple,sart = <&sart>;

			#if defined(APPLE_USE_PMP)
			power-domains = <&pmp_report_ans>, <&ps_apcie_sys_st>;
			#else
			power-domains = <&ps_ans>, <&ps_apcie_sys_st>;
			#endif
			power-domain-names = "ans", "apcie0";
			resets = <&ps_ans>;
		};

		pcie0: pcie@580000000 {
			compatible = "apple,t6030-pcie", "apple,t6020-pcie";
			device_type = "pci";

			reg = <0x5 0x80000000 0x0 0x1000000>,	/* config */
				<0x5 0x91000000 0x0 0x4000>,	/* rc */
				<0x5 0x94008000 0x0 0x4000>,	/* port0 */
				<0x5 0x95008000 0x0 0x4000>,	/* port1 */
				<0x5 0x96008000 0x0 0x4000>,	/* port2 */
				<0x5 0x97008000 0x0 0x4000>,	/* port3 */
				<0x5 0x9e020000 0x0 0x4000>,	/* phy0 */
				<0x5 0x9e024000 0x0 0x4000>,	/* phy1 */
				<0x5 0x9e028000 0x0 0x4000>,	/* phy2 */
				<0x5 0x9e02c000 0x0 0x4000>;	/* phy3 */
			reg-names = "config", "rc",
				    "port0", "port1", "port2", "port3",
				    "phy0", "phy1", "phy2", "phy3";

			interrupt-parent = <&aic>;
			interrupts = <AIC_IRQ 1038 IRQ_TYPE_LEVEL_HIGH>,
				     <AIC_IRQ 1047 IRQ_TYPE_LEVEL_HIGH>,
				     <AIC_IRQ 1056 IRQ_TYPE_LEVEL_HIGH>,
				     <AIC_IRQ 1065 IRQ_TYPE_LEVEL_HIGH>;

			msi-controller;
			msi-parent = <&pcie0>;
			msi-ranges = <&aic AIC_IRQ 1342 IRQ_TYPE_EDGE_RISING 32>;

			iommu-map = <0x100 &pcie0_dart_0 1 1>,
				    <0x200 &pcie0_dart_1 1 1>,
				    <0x300 &pcie0_dart_2 1 1>,
				    <0x400 &pcie0_dart_3 1 1>;
			iommu-map-mask = <0xff00>;

			bus-range = <0 4>;
			#address-cells = <3>;
			#size-cells = <2>;
			ranges = <0x43000000 0x5 0xa0000000 0x5 0xa0000000 0x0 0x20000000>,
				 <0x02000000 0x0 0xc0000000 0x5 0xc0000000 0x0 0x40000000>;

			power-domains = <&ps_apcie_sys_gp>;
			pinctrl-0 = <&pcie_pins>;
			pinctrl-names = "default";

			port00: pci@0,0 {
				device_type = "pci";
				reg = <0x0 0x0 0x0 0x0 0x0>;
				reset-gpios = <&pinctrl_ap 167 GPIO_ACTIVE_LOW>; // perst

				#address-cells = <3>;
				#size-cells = <2>;
				ranges;

				interrupt-controller;
				#interrupt-cells = <1>;

				interrupt-map-mask = <0 0 0 7>;
				interrupt-map = <0 0 0 1 &port00 0 0 0 0>,
						<0 0 0 2 &port00 0 0 0 1>,
						<0 0 0 3 &port00 0 0 0 2>,
						<0 0 0 4 &port00 0 0 0 3>;
			};

			port01: pci@1,0 {
				device_type = "pci";
				reg = <0x800 0x0 0x0 0x0 0x0>;
				reset-gpios = <&pinctrl_ap 168 GPIO_ACTIVE_LOW>; // perst

				#address-cells = <3>;
				#size-cells = <2>;
				ranges;

				interrupt-controller;
				#interrupt-cells = <1>;

				interrupt-map-mask = <0 0 0 7>;
				interrupt-map = <0 0 0 1 &port01 0 0 0 0>,
						<0 0 0 2 &port01 0 0 0 1>,
						<0 0 0 3 &port01 0 0 0 2>,
						<0 0 0 4 &port01 0 0 0 3>;
				status = "disabled";
			};

			port02: pci@2,0 {
				device_type = "pci";
				reg = <0x1000 0x0 0x0 0x0 0x0>;
				reset-gpios = <&pinctrl_ap 169 GPIO_ACTIVE_LOW>; // perst

				#address-cells = <3>;
				#size-cells = <2>;
				ranges;

				interrupt-controller;
				#interrupt-cells = <1>;

				interrupt-map-mask = <0 0 0 7>;
				interrupt-map = <0 0 0 1 &port02 0 0 0 0>,
						<0 0 0 2 &port02 0 0 0 1>,
						<0 0 0 3 &port02 0 0 0 2>,
						<0 0 0 4 &port02 0 0 0 3>;
				status = "disabled";
			};

			port03: pci@3,0 {
				device_type = "pci";
				reg = <0x1800 0x0 0x0 0x0 0x0>;
				reset-gpios = <&pinctrl_ap 170 GPIO_ACTIVE_LOW>; // perst

				#address-cells = <3>;
				#size-cells = <2>;
				ranges;

				interrupt-controller;
				#interrupt-cells = <1>;

				interrupt-map-mask = <0 0 0 7>;
				interrupt-map = <0 0 0 1 &port03 0 0 0 0>,
						<0 0 0 2 &port03 0 0 0 1>,
						<0 0 0 3 &port03 0 0 0 2>,
						<0 0 0 4 &port03 0 0 0 3>;
				status = "disabled";
			};
		};

		pcie0_dart_0: iommu@594000000 {
			compatible = "apple,t6030-dart", "apple,t8110-dart";
			reg = <0x5 0x94000000 0x0 0x4000>;
			#iommu-cells = <1>;
			interrupt-parent = <&aic>;
			interrupts = <AIC_IRQ 1039 IRQ_TYPE_LEVEL_HIGH>;
			power-domains = <&ps_apcie_sys_gp>;
		};

		pcie0_dart_1: iommu@595000000 {
			compatible = "apple,t6030-dart", "apple,t8110-dart";
			reg = <0x5 0x95000000 0x0 0x4000>;
			#iommu-cells = <1>;
			interrupt-parent = <&aic>;
			interrupts = <AIC_IRQ 1048 IRQ_TYPE_LEVEL_HIGH>;
			power-domains = <&ps_apcie_sys_gp>;
			status = "disabled";
		};

		pcie0_dart_2: iommu@596000000 {
			compatible = "apple,t6030-dart", "apple,t8110-dart";
			reg = <0x5 0x96000000 0x0 0x4000>;
			#iommu-cells = <1>;
			interrupt-parent = <&aic>;
			interrupts = <AIC_IRQ 1057 IRQ_TYPE_LEVEL_HIGH>;
			power-domains = <&ps_apcie_sys_gp>;
			status = "disabled";
		};

		pcie0_dart_3: iommu@597000000 {
			compatible = "apple,t6030-dart", "apple,t8110-dart";
			reg = <0x5 0x97000000 0x0 0x4000>;
			#iommu-cells = <1>;
			interrupt-parent = <&aic>;
			interrupts = <AIC_IRQ 1066 IRQ_TYPE_LEVEL_HIGH>;
			power-domains = <&ps_apcie_sys_gp>;
			status = "disabled";
		};

		dwc3_0: usb@702280000 {
			compatible = "apple,t6030-dwc3", "apple,t8103-dwc3";
			reg = <0x7 0x02280000 0x0 0xcd00>, <0x7 0x0228cd00 0x0 0x3200>;
			reg-names = "dwc3-core", "dwc3-apple";
			interrupt-parent = <&aic>;
			interrupts = <AIC_IRQ 1087 IRQ_TYPE_LEVEL_HIGH>;
			dr_mode = "otg";
			usb-role-switch;
			role-switch-default-mode = "host";
			iommus = <&dwc3_0_dart_0 0>,
				<&dwc3_0_dart_1 1>;
			power-domains = <&ps_atc0_usb>;
			resets = <&atcphy0>;
			phys = <&atcphy0 PHY_TYPE_USB2>, <&atcphy0 PHY_TYPE_USB3>;
			phy-names = "usb2-phy", "usb3-phy";
		};

		dwc3_0_dart_0: iommu@702f00000 {
			compatible = "apple,t6030-dart", "apple,t8110-dart";
			reg = <0x7 0x02f00000 0x0 0x4000>;
			interrupt-parent = <&aic>;
			interrupts = <AIC_IRQ 1091 IRQ_TYPE_LEVEL_HIGH>;
			power-domains = <&ps_atc0_usb>;
			#iommu-cells = <1>;
		};

		dwc3_0_dart_1: iommu@702f80000 {
			compatible = "apple,t6030-dart", "apple,t8110-dart";
			reg = <0x7 0x02f80000 0x0 0x4000>;
			interrupt-parent = <&aic>;
			interrupts = <AIC_IRQ 1091 IRQ_TYPE_LEVEL_HIGH>;
			power-domains = <&ps_atc0_usb>;
			#iommu-cells = <1>;
		};

		atcphy0: phy@703000000 {
			compatible = "apple,t6030-atcphy", "apple,t8122-atcphy";
			reg = <0x7 0x03000000 0x0 0x4c000>,
				<0x7 0x03050000 0x0 0x8000>,
				<0x7 0x00000000 0x0 0x8000>,
				<0x7 0x02a90000 0x0 0x4000>,
				<0x7 0x02a84000 0x0 0x4000>;
			reg-names = "core", "lpdptx", "axi2af", "usb2phy",
				"pipehandler";

			#phy-cells = <1>;
			#reset-cells = <0>;

			orientation-switch;
			mode-switch;
			power-domains = <&ps_atc0_usb>;
		};

		dwc3_1: usb@b02280000 {
			compatible = "apple,t6030-dwc3", "apple,t8103-dwc3";
			reg = <0xb 0x02280000 0x0 0xcd00>, <0xb 0x0228cd00 0x0 0x3200>;
			reg-names = "dwc3-core", "dwc3-apple";
			interrupt-parent = <&aic>;
			interrupts = <AIC_IRQ 1145 IRQ_TYPE_LEVEL_HIGH>;
			dr_mode = "otg";
			usb-role-switch;
			role-switch-default-mode = "host";
			iommus = <&dwc3_1_dart_0 0>,
				<&dwc3_1_dart_1 1>;
			power-domains = <&ps_atc1_usb>;
			resets = <&atcphy1>;
			phys = <&atcphy1 PHY_TYPE_USB2>, <&atcphy1 PHY_TYPE_USB3>;
			phy-names = "usb2-phy", "usb3-phy";
		};

		dwc3_1_dart_0: iommu@b02f00000 {
			compatible = "apple,t6030-dart", "apple,t8110-dart";
			reg = <0xb 0x02f00000 0x0 0x4000>;
			interrupt-parent = <&aic>;
			interrupts = <AIC_IRQ 1149 IRQ_TYPE_LEVEL_HIGH>;
			power-domains = <&ps_atc1_usb>;
			#iommu-cells = <1>;
		};

		dwc3_1_dart_1: iommu@b02f80000 {
			compatible = "apple,t6030-dart", "apple,t8110-dart";
			reg = <0xb 0x02f80000 0x0 0x4000>;
			interrupt-parent = <&aic>;
			interrupts = <AIC_IRQ 1149 IRQ_TYPE_LEVEL_HIGH>;
			power-domains = <&ps_atc1_usb>;
			#iommu-cells = <1>;
		};

		atcphy1: phy@b03000000 {
			compatible = "apple,t6030-atcphy", "apple,t8122-atcphy";
			reg = <0xb 0x03000000 0x0 0x4c000>,
				<0xb 0x03050000 0x0 0x8000>,
				<0xb 0x00000000 0x0 0x8000>,
				<0xb 0x02a90000 0x0 0x4000>,
				<0xb 0x02a84000 0x0 0x4000>;
			reg-names = "core", "lpdptx", "axi2af", "usb2phy",
				"pipehandler";

			#phy-cells = <1>;
			#reset-cells = <0>;

			orientation-switch;
			mode-switch;
			power-domains = <&ps_atc1_usb>;
		};

		dwc3_2: usb@f02280000 {
			compatible = "apple,t6030-dwc3", "apple,t8103-dwc3";
			reg = <0xf 0x02280000 0x0 0xcd00>, <0xf 0x0228cd00 0x0 0x3200>;
			reg-names = "dwc3-core", "dwc3-apple";
			interrupt-parent = <&aic>;
			interrupts = <AIC_IRQ 1203 IRQ_TYPE_LEVEL_HIGH>;
			dr_mode = "otg";
			usb-role-switch;
			role-switch-default-mode = "host";
			iommus = <&dwc3_2_dart_0 0>,
				<&dwc3_2_dart_1 1>;
			power-domains = <&ps_atc2_usb>;
			resets = <&atcphy2>;
			phys = <&atcphy2 PHY_TYPE_USB2>, <&atcphy2 PHY_TYPE_USB3>;
			phy-names = "usb2-phy", "usb3-phy";
		};

		dwc3_2_dart_0: iommu@f02f00000 {
			compatible = "apple,t6030-dart", "apple,t8110-dart";
			reg = <0xf 0x02f00000 0x0 0x4000>;
			interrupt-parent = <&aic>;
			interrupts = <AIC_IRQ 1207 IRQ_TYPE_LEVEL_HIGH>;
			power-domains = <&ps_atc2_usb>;
			#iommu-cells = <1>;
		};

		dwc3_2_dart_1: iommu@f02f80000 {
			compatible = "apple,t6030-dart", "apple,t8110-dart";
			reg = <0xf 0x02f80000 0x0 0x4000>;
			interrupt-parent = <&aic>;
			interrupts = <AIC_IRQ 1207 IRQ_TYPE_LEVEL_HIGH>;
			power-domains = <&ps_atc2_usb>;
			#iommu-cells = <1>;
		};

		atcphy2: phy@f03000000 {
			compatible = "apple,t6030-atcphy", "apple,t8122-atcphy";
			reg = <0xf 0x03000000 0x0 0x4c000>,
				<0xf 0x03050000 0x0 0x8000>,
				<0xf 0x00000000 0x0 0x8000>,
				<0xf 0x02a90000 0x0 0x4000>,
				<0xf 0x02a84000 0x0 0x4000>;
			reg-names = "core", "lpdptx", "axi2af", "usb2phy",
				"pipehandler";

			#phy-cells = <1>;
			#reset-cells = <0>;

			orientation-switch;
			mode-switch;
			power-domains = <&ps_atc2_usb>;
		};

	};
};

#include "t6030-pmgr.dtsi"
